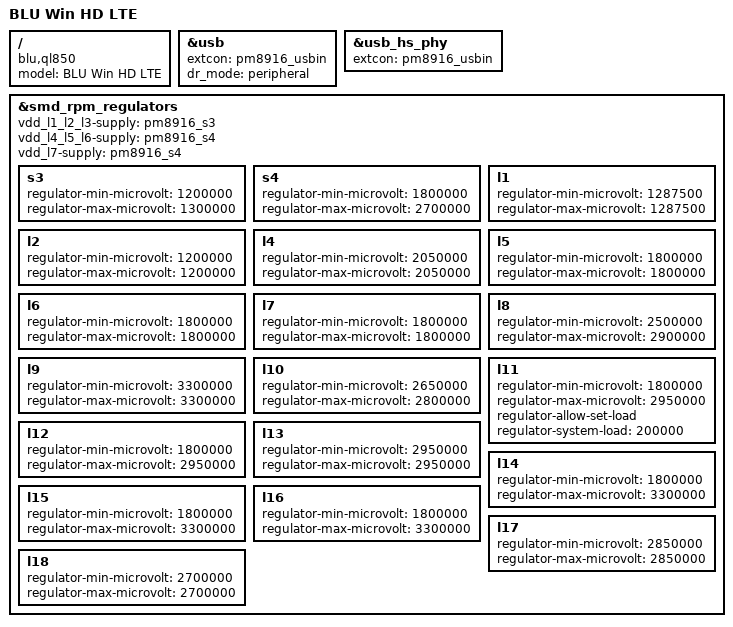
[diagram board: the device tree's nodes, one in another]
// SPDX-License-Identifier: GPL-2.0-only

/dts-v1/;

#include "msm8916-pm8916.dtsi"
#include <dt-bindings/gpio/gpio.h>

/*
 * NOTE: The original firmware from BLU can only boot ARM32 kernels.
 * Unfortunately, the firmware is signed and cannot be replaced easily.
 * There seems to be no way to boot ARM64 kernels on this device at the moment,
 * even though the hardware would support it.
 *
 * However, it is possible to use this device tree by compiling an ARM32 kernel
 * instead. For clarity and build testing this device tree is maintained next
 * to the other MSM8916 device trees. However, it is actually used through
 *   arch/arm/boot/dts/qcom-msm8916-blu-ql850.dts
 */


/ {
 	model = "BLU Win HD LTE";
 	compatible = "blu,ql850", "qcom,msm8916";
};

&usb {
	status = "okay";
	extcon = <&pm8916_usbin>;
	dr_mode = "peripheral";
};

&usb_hs_phy {
	extcon = <&pm8916_usbin>;
};

// FIXME: Verify all regulators with downstream
&smd_rpm_regulators {
	vdd_l1_l2_l3-supply = <&pm8916_s3>;
	vdd_l4_l5_l6-supply = <&pm8916_s4>;
	vdd_l7-supply = <&pm8916_s4>;

	s3 {
		regulator-min-microvolt = <1200000>;
		regulator-max-microvolt = <1300000>;
	};

	s4 {
		regulator-min-microvolt = <1800000>;
		regulator-max-microvolt = <2700000>;
	};

	l1 {
		regulator-min-microvolt = <1287500>;
		regulator-max-microvolt = <1287500>;
	};

	l2 {
		regulator-min-microvolt = <1200000>;
		regulator-max-microvolt = <1200000>;
	};

	l4 {
		regulator-min-microvolt = <2050000>;
		regulator-max-microvolt = <2050000>;
	};

	l5 {
		regulator-min-microvolt = <1800000>;
		regulator-max-microvolt = <1800000>;
	};

	l6 {
		regulator-min-microvolt = <1800000>;
		regulator-max-microvolt = <1800000>;
	};

	l7 {
		regulator-min-microvolt = <1800000>;
		regulator-max-microvolt = <1800000>;
	};

	l8 {
		regulator-min-microvolt = <2500000>;
		regulator-max-microvolt = <2900000>;
	};

	l9 {
		regulator-min-microvolt = <3300000>;
		regulator-max-microvolt = <3300000>;
	};

	l10 {
		regulator-min-microvolt = <2650000>;
		regulator-max-microvolt = <2800000>;
	};

	l11 {
		regulator-min-microvolt = <1800000>;
		regulator-max-microvolt = <2950000>;
		regulator-allow-set-load;
		regulator-system-load = <200000>;
	};

	l12 {
		regulator-min-microvolt = <1800000>;
		regulator-max-microvolt = <2950000>;
	};

	l13 {
		regulator-min-microvolt = <2950000>;
		regulator-max-microvolt = <2950000>;
	};

	l14 {
		regulator-min-microvolt = <1800000>;
		regulator-max-microvolt = <3300000>;
	};

	l15 {
		regulator-min-microvolt = <1800000>;
		regulator-max-microvolt = <3300000>;
	};

	l16 {
		regulator-min-microvolt = <1800000>;
		regulator-max-microvolt = <3300000>;
	};

	l17 {
		regulator-min-microvolt = <2850000>;
		regulator-max-microvolt = <2850000>;
	};

	l18 {
		regulator-min-microvolt = <2700000>;
		regulator-max-microvolt = <2700000>;
	};
};
